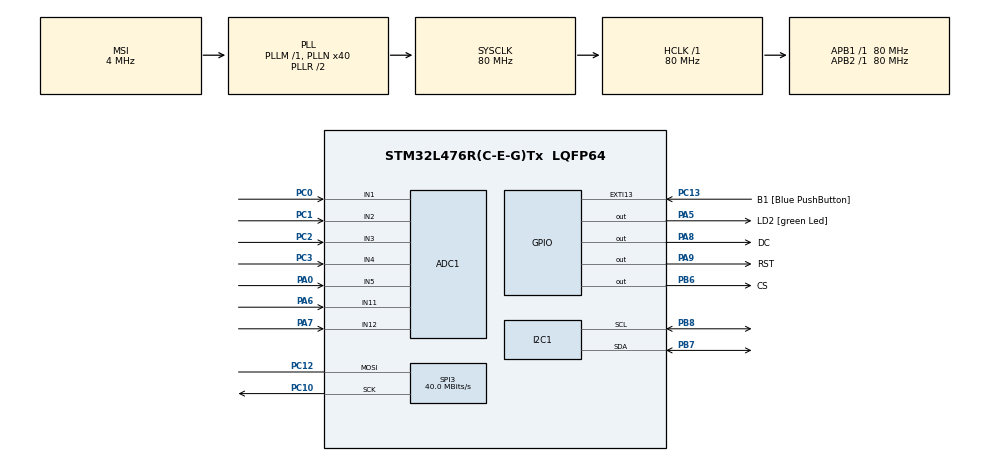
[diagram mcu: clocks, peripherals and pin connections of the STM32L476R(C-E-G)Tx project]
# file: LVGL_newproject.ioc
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ADC1.Channel-0\#ChannelRegularConversion=ADC_CHANNEL_1
ADC1.NbrOfConversionFlag=1
ADC1.OffsetNumber-0\#ChannelRegularConversion=ADC_OFFSET_NONE
ADC1.Rank-0\#ChannelRegularConversion=1
ADC1.SamplingTime-0\#ChannelRegularConversion=ADC_SAMPLETIME_2CYCLES_5
ADC1.master=1
Dma.ADC1.1.Direction=DMA_PERIPH_TO_MEMORY
Dma.ADC1.1.Instance=DMA1_Channel1
Dma.ADC1.1.MemDataAlignment=DMA_MDATAALIGN_HALFWORD
Dma.ADC1.1.MemInc=DMA_MINC_ENABLE
Dma.ADC1.1.Mode=DMA_NORMAL
Dma.ADC1.1.PeriphDataAlignment=DMA_PDATAALIGN_HALFWORD
Dma.ADC1.1.PeriphInc=DMA_PINC_DISABLE
Dma.ADC1.1.Priority=DMA_PRIORITY_LOW
Dma.Request0=SPI3_TX
Dma.Request1=ADC1
Dma.SPI3_TX.0.Direction=DMA_MEMORY_TO_PERIPH
Dma.SPI3_TX.0.Instance=DMA2_Channel2
Dma.SPI3_TX.0.MemDataAlignment=DMA_MDATAALIGN_BYTE
Dma.SPI3_TX.0.MemInc=DMA_MINC_ENABLE
Dma.SPI3_TX.0.Mode=DMA_NORMAL
Dma.SPI3_TX.0.PeriphDataAlignment=DMA_PDATAALIGN_BYTE
Dma.SPI3_TX.0.PeriphInc=DMA_PINC_DISABLE
Dma.SPI3_TX.0.Priority=DMA_PRIORITY_LOW
Mcu.Family=STM32L4
Mcu.Name=STM32L476R(C-E-G)Tx
Mcu.Package=LQFP64
NVIC.ADC1_2_IRQn=true\:0\:0\:false\:false\:true\:true\:true
NVIC.DMA1_Channel1_IRQn=true\:0\:0\:false\:false\:true\:false\:true
NVIC.DMA2_Channel2_IRQn=true\:0\:0\:false\:false\:true\:false\:true
NVIC.I2C1_ER_IRQn=true\:0\:0\:false\:false\:true\:true\:true
NVIC.I2C1_EV_IRQn=true\:0\:0\:false\:false\:true\:true\:true
NVIC.PriorityGroup=NVIC_PRIORITYGROUP_4
NVIC.SPI3_IRQn=true\:0\:0\:false\:false\:true\:true\:true
NVIC.TIM2_IRQn=true\:0\:0\:false\:false\:true\:true\:true
NVIC.TIM3_IRQn=true\:0\:0\:false\:false\:true\:true\:true
PA0.Signal=ADCx_IN5
PA13\ (JTMS-SWDIO).GPIO_Label=TMS
PA13\ (JTMS-SWDIO).Signal=SYS_JTMS-SWDIO
PA14\ (JTCK-SWCLK).GPIO_Label=TCK
PA14\ (JTCK-SWCLK).Signal=SYS_JTCK-SWCLK
PA2.Signal=USART2_TX
PA3.GPIO_Label=USART_RX
PA3.GPIO_Mode=GPIO_MODE_AF_PP
PA3.GPIO_PuPd=GPIO_NOPULL
PA3.GPIO_Speed=GPIO_SPEED_FREQ_VERY_HIGH
PA3.Signal=USART2_RX
PA5.GPIO_Label=LD2 [green Led]
PA5.GPIO_ModeDefaultOutputPP=GPIO_MODE_OUTPUT_PP
PA5.GPIO_PuPd=GPIO_NOPULL
PA5.GPIO_Speed=GPIO_SPEED_FREQ_VERY_HIGH
PA5.Signal=GPIO_Output
PA6.Signal=ADCx_IN11
PA7.Signal=ADCx_IN12
PA8.GPIO_Label=DC
PA8.GPIO_Speed=GPIO_SPEED_FREQ_VERY_HIGH
PA8.Signal=GPIO_Output
PA9.GPIO_Label=RST
PA9.GPIO_Speed=GPIO_SPEED_FREQ_VERY_HIGH
PA9.Signal=GPIO_Output
PB3\ (JTDO-TRACESWO).GPIO_Label=SWO
PB3\ (JTDO-TRACESWO).Signal=SYS_JTDO-SWO
PB6.GPIO_Label=CS
PB6.GPIO_Speed=GPIO_SPEED_FREQ_VERY_HIGH
PB6.Signal=GPIO_Output
PB7.Mode=I2C
PB7.Signal=I2C1_SDA
PB8.Mode=I2C
PB8.Signal=I2C1_SCL
PC0.Signal=ADCx_IN1
PC1.Signal=ADCx_IN2
PC10.Mode=Simplex_Bidirectional_Master
PC10.Signal=SPI3_SCK
PC12.Mode=Simplex_Bidirectional_Master
PC12.Signal=SPI3_MOSI
PC13.GPIO_Label=B1 [Blue PushButton]
PC13.GPIO_ModeDefaultEXTI=GPIO_MODE_IT_FALLING
PC13.GPIO_PuPd=GPIO_NOPULL
PC13.Signal=GPXTI13
PC14-OSC32_IN\ (PC14).Signal=RCC_OSC32_IN
PC15-OSC32_OUT\ (PC15).Signal=RCC_OSC32_OUT
PC2.Signal=ADCx_IN3
PC3.Signal=ADCx_IN4
PH0-OSC_IN\ (PH0).Signal=RCC_OSC_IN
PH1-OSC_OUT\ (PH1).Signal=RCC_OSC_OUT
ProjectManager.HeapSize=0x200
ProjectManager.StackSize=0x400
ProjectManager.TargetToolchain=STM32CubeIDE
RCC.ADCFreq_Value=32000000
RCC.AHBFreq_Value=80000000
RCC.APB1Freq_Value=80000000
RCC.APB1TimFreq_Value=80000000
RCC.APB2Freq_Value=80000000
RCC.APB2TimFreq_Value=80000000
RCC.CortexFreq_Value=80000000
RCC.HCLKFreq_Value=80000000
RCC.HSE_VALUE=8000000
RCC.HSI_VALUE=16000000
RCC.LSE_VALUE=32768
RCC.MSI_VALUE=4000000
RCC.PLLN=40
RCC.PLLSAI1N=16
RCC.PREFETCH_ENABLE=1
RCC.SYSCLKFreq_VALUE=80000000
RCC.SYSCLKSource=RCC_SYSCLKSOURCE_PLLCLK
RCC.USBFreq_Value=32000000
RCC.VCOOutputFreq_Value=160000000
SH.ADCx_IN1.0=ADC1_IN1,IN1-Single-Ended
SH.ADCx_IN11.0=ADC1_IN11,IN11-Single-Ended
SH.ADCx_IN12.0=ADC1_IN12,IN12-Single-Ended
SH.ADCx_IN2.0=ADC1_IN2,IN2-Single-Ended
SH.ADCx_IN3.0=ADC1_IN3,IN3-Single-Ended
SH.ADCx_IN4.0=ADC1_IN4,IN4-Single-Ended
SH.ADCx_IN5.0=ADC1_IN5,IN5-Single-Ended
SPI3.BaudRatePrescaler=SPI_BAUDRATEPRESCALER_2
SPI3.CalculateBaudRate=40.0 MBits/s
SPI3.DataSize=SPI_DATASIZE_8BIT
SPI3.Direction=SPI_DIRECTION_1LINE
SPI3.Mode=SPI_MODE_MASTER
SPI3.VirtualType=VM_MASTER
TIM3.Channel-PWM\ Generation1\ No\ Output=TIM_CHANNEL_1
VP_ADC1_TempSens_Input.Mode=IN-TempSens
VP_RTC_VS_RTC_Activate.Mode=RTC_Enabled
VP_TIM2_VS_ClockSourceINT.Mode=Internal
VP_TIM3_VS_ClockSourceINT.Mode=Internal
VP_TIM3_VS_no_output1.Mode=PWM Generation1 No Output
board=NUCLEO-L476RG

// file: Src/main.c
/* USER CODE BEGIN Header */
/**
  ******************************************************************************
  * @file           : main.c
  * @brief          : Main program body
  ******************************************************************************
  * @attention
  *
  * <h2><center>&copy; Copyright (c) 2023 STMicroelectronics.
  * All rights reserved.</center></h2>
  *
  * This software component is licensed by ST under BSD 3-Clause license,
  * the "License"; You may not use this file except in compliance with the
  * License. You may obtain a copy of the License at:
  *                        opensource.org/licenses/BSD-3-Clause
  *
  ******************************************************************************
  */
/* USER CODE END Header */

#include "main.h"
#include "adc.h"
#include "dma.h"
#include "i2c.h"
#include "rtc.h"
#include "spi.h"
#include "tim.h"
#include "gpio.h"

/* USER CODE BEGIN Includes */
#include "stdio.h"
#include "../lvgl/lvgl.h"
#include "../lvgl/examples/lv_examples.h"
#include "lcd_lvgl.h"
#include "LCD_1in28.h"
#include "GUI_Paint.h"
/* USER CODE END Includes */

void SystemClock_Config(void);

int main(void)
{

  /* MCU Configuration--------------------------------------------------------*/

  /* Reset of all peripherals, Initializes the Flash interface and the Systick. */
  HAL_Init();

  /* Configure the system clock */
  SystemClock_Config();

  /* Initialize all configured peripherals */
  MX_GPIO_Init();
  MX_DMA_Init();
  MX_ADC1_Init();
  MX_I2C1_Init();
  MX_RTC_Init();
  MX_SPI3_Init();
  MX_DMA_Init();
  MX_TIM2_Init();
  MX_TIM3_Init();
  /* USER CODE BEGIN 2 */
  lv_init();
  Display_init(1);
//  LCD_1in28_test();
//	printf("LCD_1IN28_test Demo\r\n");
//	DEV_Module_Init();
//
////printf("LCD_1IN28_ Init and Clear...\r\n");
//	LCD_1IN28_SetBackLight(1000);
//	LCD_1IN28_Init(VERTICAL);
//	LCD_1IN28_Clear(BLACK);
//
//
////	printf("Set Clear and Display Funtion\r\n");
//	Paint_SetClearFuntion(LCD_1IN28_Clear);
//	Paint_SetDisplayFuntion(LCD_1IN28_DrawPaint);
//
//	Paint_Clear(BLACK);
//
//	printf("drawing...\r\n");

//	Paint_DrawImage(gImage_60X60, 0, 0, 240, 240);
//	Paint_NewImage(240, 240, 0, Color)
//	Paint_DrawCircle(120,120, 120, BLUE ,DOT_PIXEL_2X2,DRAW_FILL_EMPTY);
//	printf("quit...\r\n");
//	DEV_Module_Exit();

//	lv_example_anim_2();
//	lv_example_get_started_1();
  lv_example_anim_2();
  /* USER CODE END 2 */

  /* Infinite loop */
  while (1)
  {
	  HAL_Delay(50);
	  lv_task_handler();
  }
}

void SystemClock_Config(void)
{
  RCC_OscInitTypeDef RCC_OscInitStruct = {0};
  RCC_ClkInitTypeDef RCC_ClkInitStruct = {0};
  RCC_PeriphCLKInitTypeDef PeriphClkInit = {0};

  /** Initializes the CPU, AHB and APB busses clocks
  */
  RCC_OscInitStruct.OscillatorType = RCC_OSCILLATORTYPE_LSI|RCC_OSCILLATORTYPE_MSI;
  RCC_OscInitStruct.LSIState = RCC_LSI_ON;
  RCC_OscInitStruct.MSIState = RCC_MSI_ON;
  RCC_OscInitStruct.MSICalibrationValue = 0;
  RCC_OscInitStruct.MSIClockRange = RCC_MSIRANGE_6;
  RCC_OscInitStruct.PLL.PLLState = RCC_PLL_ON;
  RCC_OscInitStruct.PLL.PLLSource = RCC_PLLSOURCE_MSI;
  RCC_OscInitStruct.PLL.PLLM = 1;
  RCC_OscInitStruct.PLL.PLLN = 40;
  RCC_OscInitStruct.PLL.PLLP = RCC_PLLP_DIV7;
  RCC_OscInitStruct.PLL.PLLQ = RCC_PLLQ_DIV2;
  RCC_OscInitStruct.PLL.PLLR = RCC_PLLR_DIV2;
  if (HAL_RCC_OscConfig(&RCC_OscInitStruct) != HAL_OK)
  {
    Error_Handler();
  }
  /** Initializes the CPU, AHB and APB busses clocks
  */
  RCC_ClkInitStruct.ClockType = RCC_CLOCKTYPE_HCLK|RCC_CLOCKTYPE_SYSCLK
                              |RCC_CLOCKTYPE_PCLK1|RCC_CLOCKTYPE_PCLK2;
  RCC_ClkInitStruct.SYSCLKSource = RCC_SYSCLKSOURCE_PLLCLK;
  RCC_ClkInitStruct.AHBCLKDivider = RCC_SYSCLK_DIV1;
  RCC_ClkInitStruct.APB1CLKDivider = RCC_HCLK_DIV1;
  RCC_ClkInitStruct.APB2CLKDivider = RCC_HCLK_DIV1;

  if (HAL_RCC_ClockConfig(&RCC_ClkInitStruct, FLASH_LATENCY_4) != HAL_OK)
  {
    Error_Handler();
  }
  PeriphClkInit.PeriphClockSelection = RCC_PERIPHCLK_RTC|RCC_PERIPHCLK_I2C1
                              |RCC_PERIPHCLK_ADC;
  PeriphClkInit.I2c1ClockSelection = RCC_I2C1CLKSOURCE_PCLK1;
  PeriphClkInit.AdcClockSelection = RCC_ADCCLKSOURCE_PLLSAI1;
  PeriphClkInit.RTCClockSelection = RCC_RTCCLKSOURCE_LSI;
  PeriphClkInit.PLLSAI1.PLLSAI1Source = RCC_PLLSOURCE_MSI;
  PeriphClkInit.PLLSAI1.PLLSAI1M = 1;
  PeriphClkInit.PLLSAI1.PLLSAI1N = 16;
  PeriphClkInit.PLLSAI1.PLLSAI1P = RCC_PLLP_DIV7;
  PeriphClkInit.PLLSAI1.PLLSAI1Q = RCC_PLLQ_DIV2;
  PeriphClkInit.PLLSAI1.PLLSAI1R = RCC_PLLR_DIV2;
  PeriphClkInit.PLLSAI1.PLLSAI1ClockOut = RCC_PLLSAI1_ADC1CLK;
  if (HAL_RCCEx_PeriphCLKConfig(&PeriphClkInit) != HAL_OK)
  {
    Error_Handler();
  }
  /** Configure the main internal regulator output voltage
  */
  if (HAL_PWREx_ControlVoltageScaling(PWR_REGULATOR_VOLTAGE_SCALE1) != HAL_OK)
  {
    Error_Handler();
  }
}

void HAL_TIM_PeriodElapsedCallback(TIM_HandleTypeDef *htim)
{
  if (htim->Instance == TIM1) {
    HAL_IncTick();
  }
}

void Error_Handler(void)
{
}

/************************ (C) COPYRIGHT STMicroelectronics *****END OF FILE****/
